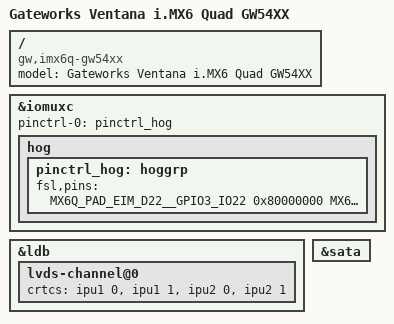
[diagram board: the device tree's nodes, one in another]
/*
 * Copyright 2013 Gateworks Corporation
 *
 * The code contained herein is licensed under the GNU General Public
 * License. You may obtain a copy of the GNU General Public License
 * Version 2 or later at the following locations:
 *
 * http://www.opensource.org/licenses/gpl-license.html
 * http://www.gnu.org/copyleft/gpl.html
 */

/dts-v1/;
#include "imx6q.dtsi"
#include "imx6qdl-gw54xx.dtsi"

/ {
	model = "Gateworks Ventana i.MX6 Quad GW54XX";
	compatible = "gw,imx6q-gw54xx", "gw,ventana", "fsl,imx6q";
};

&iomuxc {
	pinctrl-names = "default";
	pinctrl-0 = <&pinctrl_hog>;

	hog {
		pinctrl_hog: hoggrp {
			fsl,pins = <
				MX6Q_PAD_EIM_D22__GPIO3_IO22    0x80000000 /* OTG_PWR_EN */
				MX6Q_PAD_EIM_D19__GPIO3_IO19    0x80000000 /* SPINOR_CS0# */
				MX6Q_PAD_ENET_TX_EN__GPIO1_IO28 0x80000000 /* PCIE IRQ */
				MX6Q_PAD_ENET_TXD1__GPIO1_IO29  0x80000000 /* PCIE RST */
				MX6Q_PAD_GPIO_0__CCM_CLKO1      0x000130b0 /* AUD4_MCK */
				MX6Q_PAD_GPIO_2__GPIO1_IO02     0x80000000 /* CAN_STBY */
				MX6Q_PAD_GPIO_17__GPIO7_IO12    0x80000000 /* TOUCH_IRQ# */
				MX6Q_PAD_KEY_COL0__GPIO4_IO06   0x80000000 /* user1 led */
				MX6Q_PAD_KEY_ROW0__GPIO4_IO07   0x80000000 /* user2 led */
				MX6Q_PAD_KEY_ROW4__GPIO4_IO15   0x80000000 /* user3 led */
				MX6Q_PAD_SD1_DAT0__GPIO1_IO16   0x80000000 /* USBHUB_RST# */
				MX6Q_PAD_SD1_DAT3__GPIO1_IO21   0x80000000 /* MIPI_DIO */
			 >;
		};
	};
};

&ldb {  
	status = "okay";
	lvds-channel@0 {
		crtcs = <&ipu1 0>, <&ipu1 1>, <&ipu2 0>, <&ipu2 1>;
	};
};

&sata {
	status = "okay";
};
